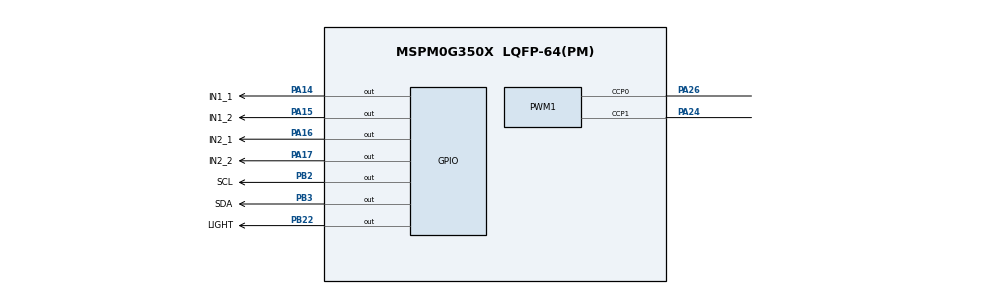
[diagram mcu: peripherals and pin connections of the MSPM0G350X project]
/**
 * @cliArgs --device "MSPM0G350X" --part "Default" --package "LQFP-64(PM)" --product "mspm0_sdk@2.10.00.04"
 * @versions {"tool":"1.27.1+4634"}
 */

/**
 * Import the modules used in this configuration.
 */
const GPIO   = scripting.addModule("/ti/driverlib/GPIO", {}, false);
const GPIO1  = GPIO.addInstance();
const GPIO2  = GPIO.addInstance();
const GPIO3  = GPIO.addInstance();
const GPIO4  = GPIO.addInstance();
const GPIO5  = GPIO.addInstance();
const PWM    = scripting.addModule("/ti/driverlib/PWM", {}, false);
const PWM1   = PWM.addInstance();
const SYSCTL = scripting.addModule("/ti/driverlib/SYSCTL");

/**
 * Write custom configuration values to the imported modules.
 */
const divider2       = system.clockTree["HFCLK4MFPCLKDIV"];
divider2.divideValue = 10;

const divider9       = system.clockTree["UDIV"];
divider9.divideValue = 2;

const gate8  = system.clockTree["MFPCLKGATE"];
gate8.enable = true;

const mux4       = system.clockTree["EXHFMUX"];
mux4.inputSelect = "EXHFMUX_XTAL";

const mux8       = system.clockTree["HSCLKMUX"];
mux8.inputSelect = "HSCLKMUX_SYSPLL2X";

const mux10       = system.clockTree["MFPCLKMUX"];
mux10.inputSelect = "MFPCLKMUX_HFCLK";

const mux12       = system.clockTree["SYSPLLMUX"];
mux12.inputSelect = "zSYSPLLMUX_HFCLK";

const pinFunction4     = system.clockTree["HFXT"];
pinFunction4.enable    = true;
pinFunction4.inputFreq = 40;

GPIO1.$name                              = "OLED";
GPIO1.port                               = "PORTB";
GPIO1.portSegment                        = "Lower";
GPIO1.associatedPins.create(2);
GPIO1.associatedPins[0].$name            = "SCL";
GPIO1.associatedPins[0].initialValue     = "SET";
GPIO1.associatedPins[0].internalResistor = "PULL_UP";
GPIO1.associatedPins[0].assignedPin      = "2";
GPIO1.associatedPins[0].pin.$assign      = "PB2";
GPIO1.associatedPins[1].$name            = "SDA";
GPIO1.associatedPins[1].initialValue     = "SET";
GPIO1.associatedPins[1].internalResistor = "PULL_UP";
GPIO1.associatedPins[1].assignedPin      = "3";
GPIO1.associatedPins[1].pin.$assign      = "PB3";

const Board = scripting.addModule("/ti/driverlib/Board", {}, false);

GPIO2.$name                         = "LED";
GPIO2.port                          = "PORTB";
GPIO2.portSegment                   = "Upper";
GPIO2.associatedPins[0].$name       = "LIGHT";
GPIO2.associatedPins[0].assignedPin = "22";
GPIO2.associatedPins[0].pin.$assign = "PB22";

GPIO3.$name                              = "encode";
GPIO3.port                               = "PORTA";
GPIO3.portSegment                        = "Lower";
GPIO3.associatedPins.create(4);
GPIO3.associatedPins[0].direction        = "INPUT";
GPIO3.associatedPins[0].assignedPin      = "0";
GPIO3.associatedPins[0].interruptEn      = true;
GPIO3.associatedPins[0].internalResistor = "PULL_DOWN";
GPIO3.associatedPins[0].polarity         = "RISE";
GPIO3.associatedPins[0].$name            = "LEFT_A";
GPIO3.associatedPins[1].direction        = "INPUT";
GPIO3.associatedPins[1].assignedPin      = "1";
GPIO3.associatedPins[1].internalResistor = "PULL_DOWN";
GPIO3.associatedPins[1].$name            = "LEFT_B";
GPIO3.associatedPins[2].$name            = "RIGHT_A";
GPIO3.associatedPins[2].direction        = "INPUT";
GPIO3.associatedPins[2].interruptEn      = true;
GPIO3.associatedPins[2].polarity         = "RISE";
GPIO3.associatedPins[2].internalResistor = "PULL_DOWN";
GPIO3.associatedPins[2].assignedPin      = "8";
GPIO3.associatedPins[3].$name            = "RIGHT_B";
GPIO3.associatedPins[3].assignedPin      = "9";
GPIO3.associatedPins[3].direction        = "INPUT";
GPIO3.associatedPins[3].internalResistor = "PULL_DOWN";

GPIO4.$name                              = "WHEEL_CTRL";
GPIO4.port                               = "PORTA";
GPIO4.associatedPins.create(4);
GPIO4.associatedPins[0].$name            = "IN1_1";
GPIO4.associatedPins[0].internalResistor = "PULL_DOWN";
GPIO4.associatedPins[0].assignedPin      = "14";
GPIO4.associatedPins[0].pin.$assign      = "PA14";
GPIO4.associatedPins[1].$name            = "IN1_2";
GPIO4.associatedPins[1].internalResistor = "PULL_DOWN";
GPIO4.associatedPins[1].assignedPin      = "15";
GPIO4.associatedPins[1].pin.$assign      = "PA15";
GPIO4.associatedPins[2].$name            = "IN2_1";
GPIO4.associatedPins[2].internalResistor = "PULL_DOWN";
GPIO4.associatedPins[2].assignedPin      = "16";
GPIO4.associatedPins[2].pin.$assign      = "PA16";
GPIO4.associatedPins[3].$name            = "IN2_2";
GPIO4.associatedPins[3].internalResistor = "PULL_DOWN";
GPIO4.associatedPins[3].assignedPin      = "17";
GPIO4.associatedPins[3].pin.$assign      = "PA17";

GPIO5.$name                                 = "IR_SENSOR";
GPIO5.associatedPins.create(8);
GPIO5.associatedPins[0].$name               = "IR1";
GPIO5.associatedPins[0].direction           = "INPUT";
GPIO5.associatedPins[0].internalResistor    = "PULL_UP";
GPIO5.associatedPins[0].assignedPort        = "PORTA";
GPIO5.associatedPins[0].assignedPortSegment = "Upper";
GPIO5.associatedPins[0].assignedPin         = "28";
GPIO5.associatedPins[1].$name               = "IR2";
GPIO5.associatedPins[1].direction           = "INPUT";
GPIO5.associatedPins[1].internalResistor    = "PULL_UP";
GPIO5.associatedPins[1].assignedPort        = "PORTA";
GPIO5.associatedPins[1].assignedPin         = "31";
GPIO5.associatedPins[2].$name               = "IR3";
GPIO5.associatedPins[2].internalResistor    = "PULL_UP";
GPIO5.associatedPins[2].assignedPort        = "PORTB";
GPIO5.associatedPins[2].assignedPin         = "4";
GPIO5.associatedPins[2].direction           = "INPUT";
GPIO5.associatedPins[3].$name               = "IR4";
GPIO5.associatedPins[3].direction           = "INPUT";
GPIO5.associatedPins[3].internalResistor    = "PULL_UP";
GPIO5.associatedPins[3].assignedPort        = "PORTB";
GPIO5.associatedPins[3].assignedPin         = "5";
GPIO5.associatedPins[4].$name               = "IR5";
GPIO5.associatedPins[4].direction           = "INPUT";
GPIO5.associatedPins[4].internalResistor    = "PULL_UP";
GPIO5.associatedPins[4].assignedPort        = "PORTA";
GPIO5.associatedPins[4].assignedPin         = "10";
GPIO5.associatedPins[5].$name               = "IR6";
GPIO5.associatedPins[5].direction           = "INPUT";
GPIO5.associatedPins[5].assignedPort        = "PORTA";
GPIO5.associatedPins[5].assignedPin         = "11";
GPIO5.associatedPins[5].internalResistor    = "PULL_UP";
GPIO5.associatedPins[6].$name               = "IR7";
GPIO5.associatedPins[6].direction           = "INPUT";
GPIO5.associatedPins[6].internalResistor    = "PULL_UP";
GPIO5.associatedPins[6].assignedPort        = "PORTB";
GPIO5.associatedPins[6].assignedPin         = "12";
GPIO5.associatedPins[7].$name               = "IR8";
GPIO5.associatedPins[7].direction           = "INPUT";
GPIO5.associatedPins[7].internalResistor    = "PULL_UP";
GPIO5.associatedPins[7].assignedPort        = "PORTB";
GPIO5.associatedPins[7].assignedPin         = "13";

PWM1.$name                              = "WHEEL";
PWM1.clockDivider                       = 8;
PWM1.timerCount                         = 1001;
PWM1.peripheral.ccp0Pin.$assign         = "PA26";
PWM1.peripheral.ccp1Pin.$assign         = "PA24";
PWM1.PWM_CHANNEL_0.$name                = "ti_driverlib_pwm_PWMTimerCC0";
PWM1.PWM_CHANNEL_1.$name                = "ti_driverlib_pwm_PWMTimerCC1";
PWM1.ccp0PinConfig.$name                = "ti_driverlib_gpio_GPIOPinGeneric0";
PWM1.ccp0PinConfig.direction            = scripting.forceWrite("OUTPUT");
PWM1.ccp0PinConfig.hideOutputInversion  = scripting.forceWrite(false);
PWM1.ccp0PinConfig.onlyInternalResistor = scripting.forceWrite(false);
PWM1.ccp0PinConfig.passedPeripheralType = scripting.forceWrite("Digital");
PWM1.ccp1PinConfig.$name                = "ti_driverlib_gpio_GPIOPinGeneric1";
PWM1.ccp1PinConfig.direction            = scripting.forceWrite("OUTPUT");
PWM1.ccp1PinConfig.hideOutputInversion  = scripting.forceWrite(false);
PWM1.ccp1PinConfig.onlyInternalResistor = scripting.forceWrite(false);
PWM1.ccp1PinConfig.passedPeripheralType = scripting.forceWrite("Digital");

SYSCTL.forceDefaultClkConfig = true;

/**
 * Pinmux solution for unlocked pins/peripherals. This ensures that minor changes to the automatic solver in a future
 * version of the tool will not impact the pinmux you originally saw.  These lines can be completely deleted in order to
 * re-solve from scratch.
 */
pinFunction4.peripheral.$suggestSolution           = "SYSCTL";
pinFunction4.peripheral.hfxInPin.$suggestSolution  = "PA5";
pinFunction4.peripheral.hfxOutPin.$suggestSolution = "PA6";
Board.peripheral.$suggestSolution                  = "DEBUGSS";
Board.peripheral.swclkPin.$suggestSolution         = "PA20";
Board.peripheral.swdioPin.$suggestSolution         = "PA19";
GPIO3.associatedPins[0].pin.$suggestSolution       = "PA0";
GPIO3.associatedPins[1].pin.$suggestSolution       = "PA1";
GPIO3.associatedPins[2].pin.$suggestSolution       = "PA8";
GPIO3.associatedPins[3].pin.$suggestSolution       = "PA9";
GPIO5.associatedPins[0].pin.$suggestSolution       = "PA28";
GPIO5.associatedPins[1].pin.$suggestSolution       = "PA31";
GPIO5.associatedPins[2].pin.$suggestSolution       = "PB4";
GPIO5.associatedPins[3].pin.$suggestSolution       = "PB5";
GPIO5.associatedPins[4].pin.$suggestSolution       = "PA10";
GPIO5.associatedPins[5].pin.$suggestSolution       = "PA11";
GPIO5.associatedPins[6].pin.$suggestSolution       = "PB12";
GPIO5.associatedPins[7].pin.$suggestSolution       = "PB13";
PWM1.peripheral.$suggestSolution                   = "TIMG7";
SYSCTL.peripheral.$suggestSolution                 = "SYSCTL";
